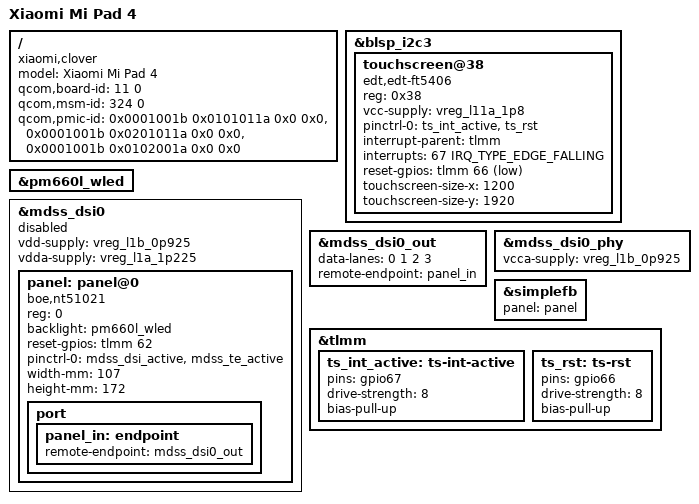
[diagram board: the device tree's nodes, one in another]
// SPDX-License-Identifier: GPL-2.0-only
/*
 * Copyright (c) 2020, Mark Hargreaves <clashclanacc2602@gmail.com>
 */

/dts-v1/;
#include "sdm660-xiaomi-clover-common.dtsi"

/ {
	model = "Xiaomi Mi Pad 4";	
	compatible = "xiaomi,clover", "qcom,sdm660";
	qcom,board-id = <11 0>;
	qcom,msm-id = <324 0>;
	qcom,pmic-id = <0x0001001b 0x0101011a 0x0 0x0>, <0x0001001b 0x0201011a 0x0 0x0>,<0x0001001b 0x0102001a 0x0 0x0>;
};

&blsp_i2c3 {
	status = "okay";

	touchscreen@38 {
		compatible = "edt,edt-ft5406", "edt,edt-ft5x06";
		reg = <0x38>;
		vcc-supply = <&vreg_l11a_1p8>;
		pinctrl-0 = <&ts_int_active &ts_rst>;
		pinctrl-names = "default";
		interrupt-parent = <&tlmm>;
		interrupts = <67 IRQ_TYPE_EDGE_FALLING>;
		reset-gpios = <&tlmm 66 GPIO_ACTIVE_LOW>;
		touchscreen-size-x = <1200>;
		touchscreen-size-y = <1920>;
	};
};

&pm660l_wled {
	status = "okay";
};

&mdss_dsi0 {
	status = "disabled";

	#address-cells = <1>;
	#size-cells = <0>;
	vdd-supply = <&vreg_l1b_0p925>;
	vdda-supply = <&vreg_l1a_1p225>;
	//vdda-1p2-supply = <0x109>; // pm660_ldoa1
	//vdda-0p9-supply = <0x105>; // pm660l_ldob1
	//vdda-3p3-supply = <0x197>; // pm660l_ldob6
	//wqhd-vddio-supply = <0x17e>; // pm660_ldoa11

	panel: panel@0 {
		compatible = "boe,nt51021";
		reg = <0>;

		backlight = <&pm660l_wled>;

		reset-gpios = <&tlmm 62 GPIO_ACTIVE_HIGH>; // not used by panel-simple
		//disp-te-gpios = <&pm660l_gpios GPIO_ACTIVE_HIGH>; // used by msm dsi host

		pinctrl-names = "default";
		pinctrl-0 = <&mdss_dsi_active &mdss_te_active>;

		//pp1800-supply = <&vreg_l11a_1p8>; // wqhd-vddio-supply
		// supply is the same for touchscreen

		width-mm = <107>;
		height-mm = <172>;

		port {
			panel_in: endpoint {
				remote-endpoint = <&mdss_dsi0_out>;
			};
		};
	};
};

&mdss_dsi0_out {
	data-lanes = <0 1 2 3>;
	remote-endpoint = <&panel_in>;
};

&mdss_dsi0_phy {
	vcca-supply = <&vreg_l1b_0p925>;
	status = "okay";
};

&simplefb {
	/* In order to allow simledrm framebuffer to know panel
	 * physical size to allow userspace to do proper DPI scaling */
	panel = <&panel>;
};

&tlmm {
	ts_int_active: ts-int-active {
		pins = "gpio67";
		drive-strength = <8>;
		bias-pull-up;
	};

	ts_rst: ts-rst {
		pins = "gpio66";
		drive-strength = <8>;
		bias-pull-up;
	};
};
